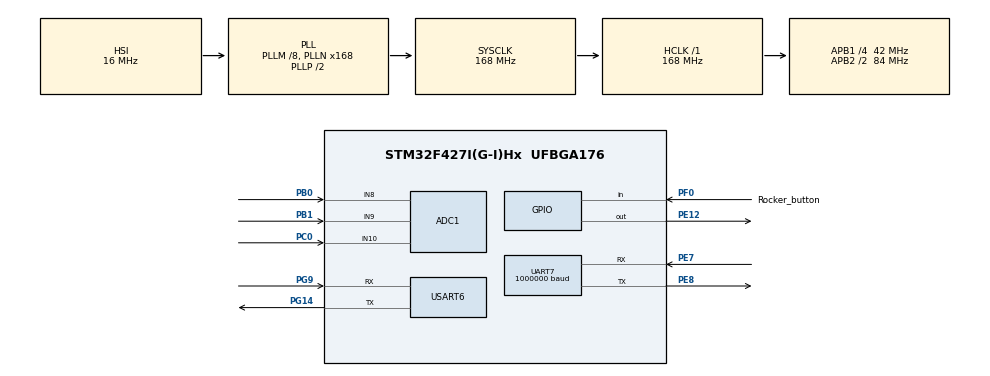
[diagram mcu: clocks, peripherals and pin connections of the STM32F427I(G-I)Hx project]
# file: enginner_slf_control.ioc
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ADC1.Channel-0\#ChannelRegularConversion=ADC_CHANNEL_8
ADC1.Channel-1\#ChannelRegularConversion=ADC_CHANNEL_9
ADC1.Channel-3\#ChannelRegularConversion=ADC_CHANNEL_10
ADC1.ContinuousConvMode=DISABLE
ADC1.DiscontinuousConvMode=ENABLE
ADC1.InjNumberOfConversion=0
ADC1.NbrOfConversion=3
ADC1.NbrOfConversionFlag=1
ADC1.Rank-0\#ChannelRegularConversion=1
ADC1.Rank-1\#ChannelRegularConversion=2
ADC1.Rank-3\#ChannelRegularConversion=3
ADC1.SamplingTime-0\#ChannelRegularConversion=ADC_SAMPLETIME_3CYCLES
ADC1.SamplingTime-1\#ChannelRegularConversion=ADC_SAMPLETIME_3CYCLES
ADC1.SamplingTime-3\#ChannelRegularConversion=ADC_SAMPLETIME_3CYCLES
ADC1.ScanConvMode=ENABLE
ADC1.master=1
Dma.Request0=USART6_RX
Dma.Request1=USART6_TX
Dma.USART6_RX.0.Direction=DMA_PERIPH_TO_MEMORY
Dma.USART6_RX.0.FIFOMode=DMA_FIFOMODE_DISABLE
Dma.USART6_RX.0.Instance=DMA2_Stream1
Dma.USART6_RX.0.MemDataAlignment=DMA_MDATAALIGN_BYTE
Dma.USART6_RX.0.MemInc=DMA_MINC_ENABLE
Dma.USART6_RX.0.Mode=DMA_NORMAL
Dma.USART6_RX.0.PeriphDataAlignment=DMA_PDATAALIGN_BYTE
Dma.USART6_RX.0.PeriphInc=DMA_PINC_DISABLE
Dma.USART6_RX.0.Priority=DMA_PRIORITY_VERY_HIGH
Dma.USART6_TX.1.Direction=DMA_MEMORY_TO_PERIPH
Dma.USART6_TX.1.FIFOMode=DMA_FIFOMODE_DISABLE
Dma.USART6_TX.1.Instance=DMA2_Stream6
Dma.USART6_TX.1.MemDataAlignment=DMA_MDATAALIGN_BYTE
Dma.USART6_TX.1.MemInc=DMA_MINC_ENABLE
Dma.USART6_TX.1.Mode=DMA_NORMAL
Dma.USART6_TX.1.PeriphDataAlignment=DMA_PDATAALIGN_BYTE
Dma.USART6_TX.1.PeriphInc=DMA_PINC_DISABLE
Dma.USART6_TX.1.Priority=DMA_PRIORITY_VERY_HIGH
FREERTOS.Tasks01=defaultTask,0,128,StartDefaultTask,Default,NULL,Dynamic,NULL,NULL
Mcu.Family=STM32F4
Mcu.Name=STM32F427I(G-I)Hx
Mcu.Package=UFBGA176
NVIC.DMA2_Stream1_IRQn=true\:5\:0\:false\:false\:true\:true\:false\:true\:true
NVIC.DMA2_Stream6_IRQn=true\:5\:0\:false\:false\:true\:true\:false\:true\:true
NVIC.PriorityGroup=NVIC_PRIORITYGROUP_4
NVIC.UART7_IRQn=true\:5\:0\:false\:false\:true\:true\:true\:true\:true
NVIC.USART6_IRQn=true\:5\:0\:false\:false\:true\:true\:true\:true\:true
PA13.Mode=Serial_Wire
PA13.Signal=SYS_JTMS-SWDIO
PA14.Mode=Serial_Wire
PA14.Signal=SYS_JTCK-SWCLK
PB0.Signal=ADCx_IN8
PB1.Signal=ADCx_IN9
PC0.Signal=ADCx_IN10
PE12.GPIO_PuPd=GPIO_PULLUP
PE12.PinState=GPIO_PIN_SET
PE12.Signal=GPIO_Output
PE7.Mode=Asynchronous
PE7.Signal=UART7_RX
PE8.Mode=Asynchronous
PE8.Signal=UART7_TX
PF0.GPIO_Label=Rocker_button
PF0.GPIO_PuPd=GPIO_PULLDOWN
PF0.Signal=GPIO_Input
PG14.Mode=Asynchronous
PG14.Signal=USART6_TX
PG9.Mode=Asynchronous
PG9.Signal=USART6_RX
PH0/OSC_IN.Mode=HSE-External-Oscillator
PH0/OSC_IN.Signal=RCC_OSC_IN
PH1/OSC_OUT.Mode=HSE-External-Oscillator
PH1/OSC_OUT.Signal=RCC_OSC_OUT
ProjectManager.HeapSize=0x200
ProjectManager.StackSize=0x400
ProjectManager.TargetToolchain=MDK-ARM V5.32
RCC.48MHZClocksFreq_Value=84000000
RCC.AHBFreq_Value=168000000
RCC.APB1CLKDivider=RCC_HCLK_DIV4
RCC.APB1Freq_Value=42000000
RCC.APB1TimFreq_Value=84000000
RCC.APB2CLKDivider=RCC_HCLK_DIV2
RCC.APB2Freq_Value=84000000
RCC.APB2TimFreq_Value=168000000
RCC.CortexFreq_Value=168000000
RCC.HCLKFreq_Value=168000000
RCC.HSE_VALUE=12000000
RCC.HSI_VALUE=16000000
RCC.LSE_VALUE=32768
RCC.PLLM=8
RCC.PLLN=168
RCC.SYSCLKFreq_VALUE=168000000
RCC.SYSCLKSource=RCC_SYSCLKSOURCE_PLLCLK
RCC.VCOOutputFreq_Value=336000000
SH.ADCx_IN10.0=ADC1_IN10,IN10
SH.ADCx_IN8.0=ADC1_IN8,IN8
SH.ADCx_IN9.0=ADC1_IN9,IN9
UART7.BaudRate=1000000
UART7.VirtualMode=Asynchronous
USART6.VirtualMode=VM_ASYNC
VP_FREERTOS_VS_CMSIS_V1.Mode=CMSIS_V1
board=custom

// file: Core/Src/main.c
/* USER CODE BEGIN Header */
/**
  ******************************************************************************
  * @file           : main.c
  * @brief          : Main program body
  ******************************************************************************
  * @attention
  *
  * Copyright (c) 2025 STMicroelectronics.
  * All rights reserved.
  *
  * This software is licensed under terms that can be found in the LICENSE file
  * in the root directory of this software component.
  * If no LICENSE file comes with this software, it is provided AS-IS.
  *
  ******************************************************************************
  */
/* USER CODE END Header */
#include "main.h"
#include "cmsis_os.h"
#include "adc.h"
#include "dma.h"
#include "usart.h"
#include "gpio.h"

void SystemClock_Config(void);
void MX_FREERTOS_Init(void);

int main(void)
{

  /* MCU Configuration--------------------------------------------------------*/

  /* Reset of all peripherals, Initializes the Flash interface and the Systick. */
  HAL_Init();

  /* Configure the system clock */
  SystemClock_Config();

  /* Initialize all configured peripherals */
  MX_GPIO_Init();
  MX_DMA_Init();
  MX_UART7_Init();
  MX_ADC1_Init();
  MX_USART6_UART_Init();

  /* Call init function for freertos objects (in cmsis_os2.c) */
  MX_FREERTOS_Init();

  /* Start scheduler */
  osKernelStart();

  /* We should never get here as control is now taken by the scheduler */

  /* Infinite loop */
  while (1)
  {

  }
}

void SystemClock_Config(void)
{
  RCC_OscInitTypeDef RCC_OscInitStruct = {0};
  RCC_ClkInitTypeDef RCC_ClkInitStruct = {0};

  /** Configure the main internal regulator output voltage
  */
  __HAL_RCC_PWR_CLK_ENABLE();
  __HAL_PWR_VOLTAGESCALING_CONFIG(PWR_REGULATOR_VOLTAGE_SCALE1);

  /** Initializes the RCC Oscillators according to the specified parameters
  * in the RCC_OscInitTypeDef structure.
  */
  RCC_OscInitStruct.OscillatorType = RCC_OSCILLATORTYPE_HSI;
  RCC_OscInitStruct.HSIState = RCC_HSI_ON;
  RCC_OscInitStruct.HSICalibrationValue = RCC_HSICALIBRATION_DEFAULT;
  RCC_OscInitStruct.PLL.PLLState = RCC_PLL_ON;
  RCC_OscInitStruct.PLL.PLLSource = RCC_PLLSOURCE_HSI;
  RCC_OscInitStruct.PLL.PLLM = 8;
  RCC_OscInitStruct.PLL.PLLN = 168;
  RCC_OscInitStruct.PLL.PLLP = RCC_PLLP_DIV2;
  RCC_OscInitStruct.PLL.PLLQ = 4;
  if (HAL_RCC_OscConfig(&RCC_OscInitStruct) != HAL_OK)
  {
    Error_Handler();
  }

  /** Initializes the CPU, AHB and APB buses clocks
  */
  RCC_ClkInitStruct.ClockType = RCC_CLOCKTYPE_HCLK|RCC_CLOCKTYPE_SYSCLK
                              |RCC_CLOCKTYPE_PCLK1|RCC_CLOCKTYPE_PCLK2;
  RCC_ClkInitStruct.SYSCLKSource = RCC_SYSCLKSOURCE_PLLCLK;
  RCC_ClkInitStruct.AHBCLKDivider = RCC_SYSCLK_DIV1;
  RCC_ClkInitStruct.APB1CLKDivider = RCC_HCLK_DIV4;
  RCC_ClkInitStruct.APB2CLKDivider = RCC_HCLK_DIV2;

  if (HAL_RCC_ClockConfig(&RCC_ClkInitStruct, FLASH_LATENCY_5) != HAL_OK)
  {
    Error_Handler();
  }
}

void Error_Handler(void)
{
  __disable_irq();
  while (1)
  {
  }
}

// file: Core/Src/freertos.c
/* USER CODE BEGIN Header */
/**
  ******************************************************************************
  * File Name          : freertos.c
  * Description        : Code for freertos applications
  ******************************************************************************
  * @attention
  *
  * Copyright (c) 2025 STMicroelectronics.
  * All rights reserved.
  *
  * This software is licensed under terms that can be found in the LICENSE file
  * in the root directory of this software component.
  * If no LICENSE file comes with this software, it is provided AS-IS.
  *
  ******************************************************************************
  */
/* USER CODE END Header */

#include "FreeRTOS.h"
#include "task.h"
#include "main.h"
#include "cmsis_os.h"

/* USER CODE BEGIN Includes */
#include "self_control_task.h"
#include "usart_communicate.h"
/* USER CODE END Includes */

/* USER CODE BEGIN Variables */

osThreadId selfcontrolTaskHandle;
osThreadId usartcommunicateTaskHandle;

/* USER CODE END Variables */
osThreadId defaultTaskHandle;

void StartDefaultTask(void const * argument);

void MX_FREERTOS_Init(void); /* (MISRA C 2004 rule 8.1) */

/* GetIdleTaskMemory prototype (linked to static allocation support) */
void vApplicationGetIdleTaskMemory( StaticTask_t **ppxIdleTaskTCBBuffer, StackType_t **ppxIdleTaskStackBuffer, uint32_t *pulIdleTaskStackSize );

/* USER CODE BEGIN GET_IDLE_TASK_MEMORY */
static StaticTask_t xIdleTaskTCBBuffer;
static StackType_t xIdleStack[configMINIMAL_STACK_SIZE];

void vApplicationGetIdleTaskMemory( StaticTask_t **ppxIdleTaskTCBBuffer, StackType_t **ppxIdleTaskStackBuffer, uint32_t *pulIdleTaskStackSize )
{
  *ppxIdleTaskTCBBuffer = &xIdleTaskTCBBuffer;
  *ppxIdleTaskStackBuffer = &xIdleStack[0];
  *pulIdleTaskStackSize = configMINIMAL_STACK_SIZE;
  /* place for user code */
}
/* USER CODE END GET_IDLE_TASK_MEMORY */

void MX_FREERTOS_Init(void) {

  /* Create the thread(s) */
  /* definition and creation of defaultTask */
  osThreadDef(defaultTask, StartDefaultTask, osPriorityNormal, 0, 128);
  defaultTaskHandle = osThreadCreate(osThread(defaultTask), NULL);

  /* USER CODE BEGIN RTOS_THREADS */
  /* add threads, ... */
	osThreadDef(selfcontrolTask, self_control_task, osPriorityNormal, 0, 256);
  selfcontrolTaskHandle = osThreadCreate(osThread(selfcontrolTask), NULL);

	osThreadDef(usartcommunicateTask, usart_communicate_task, osPriorityNormal, 0, 256);
  usartcommunicateTaskHandle = osThreadCreate(osThread(usartcommunicateTask), NULL);
  /* USER CODE END RTOS_THREADS */

}

void StartDefaultTask(void const * argument)
{
  for(;;)
  {
    osDelay(1);
  }
}
